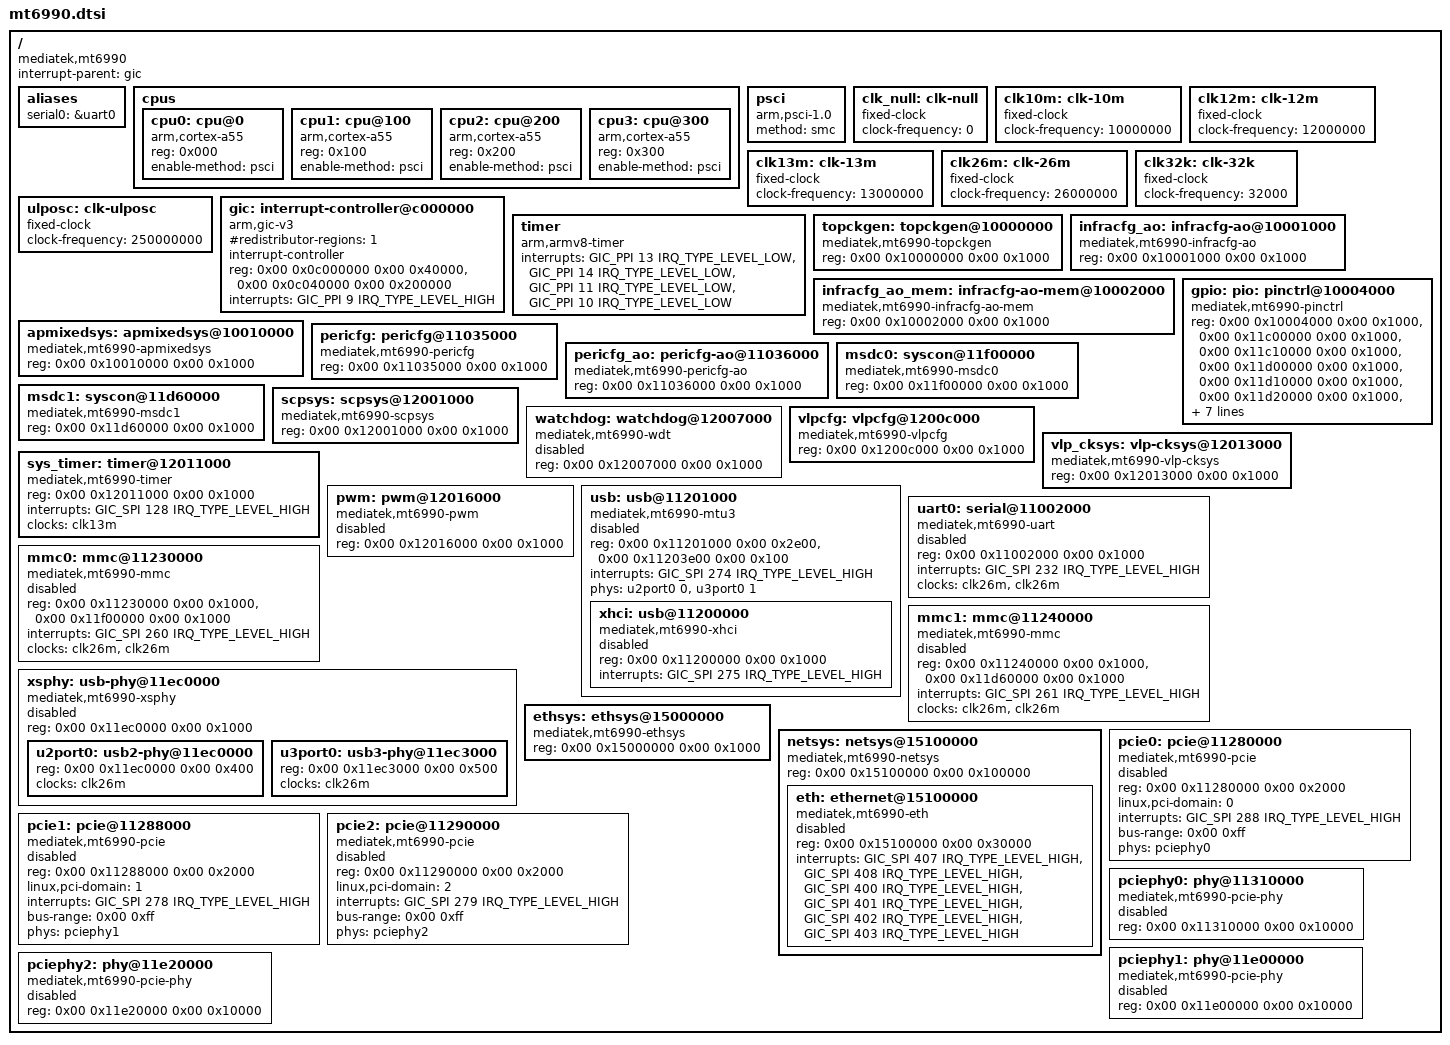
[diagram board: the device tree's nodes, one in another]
// SPDX-License-Identifier: GPL-2.0-only OR MIT
/*
 * MediaTek MT6990 / T830 SoC device tree.
 *
 * Source policy:
 *   - SoC facts are reconstructed from the running LG6851F live FDT
 *     (/sys/firmware/fdt) and the official boot_a DTB decompile.
 *   - Layout follows Linux/OpenWrt mainline-style MediaTek DTSI practice.
 *
 * This file describes MT6990 SoC blocks only. LG6851F board hardware remains
 * in mt6990-fiberhome-lg6851f.dts.
 */

#include <dt-bindings/interrupt-controller/arm-gic.h>
#include <dt-bindings/interrupt-controller/irq.h>
#include <dt-bindings/gpio/gpio.h>

/ {
	compatible = "mediatek,mt6990";
	interrupt-parent = <&gic>;
	#address-cells = <2>;
	#size-cells = <2>;

	aliases {
		serial0 = &uart0;
	};

	cpus {
		#address-cells = <1>;
		#size-cells = <0>;

		cpu0: cpu@0 {
			device_type = "cpu";
			compatible = "arm,cortex-a55";
			reg = <0x000>;
			enable-method = "psci";
		};

		cpu1: cpu@100 {
			device_type = "cpu";
			compatible = "arm,cortex-a55";
			reg = <0x100>;
			enable-method = "psci";
		};

		cpu2: cpu@200 {
			device_type = "cpu";
			compatible = "arm,cortex-a55";
			reg = <0x200>;
			enable-method = "psci";
		};

		cpu3: cpu@300 {
			device_type = "cpu";
			compatible = "arm,cortex-a55";
			reg = <0x300>;
			enable-method = "psci";
		};
	};

	psci {
		compatible = "arm,psci-1.0";
		method = "smc";
	};

	clk_null: clk-null {
		compatible = "fixed-clock";
		#clock-cells = <0>;
		clock-frequency = <0>;
	};

	clk10m: clk-10m {
		compatible = "fixed-clock";
		#clock-cells = <0>;
		clock-frequency = <10000000>;
	};

	clk12m: clk-12m {
		compatible = "fixed-clock";
		#clock-cells = <0>;
		clock-frequency = <12000000>;
	};

	clk13m: clk-13m {
		compatible = "fixed-clock";
		#clock-cells = <0>;
		clock-frequency = <13000000>;
	};

	clk26m: clk-26m {
		compatible = "fixed-clock";
		#clock-cells = <0>;
		clock-frequency = <26000000>;
	};

	clk32k: clk-32k {
		compatible = "fixed-clock";
		#clock-cells = <0>;
		clock-frequency = <32000>;
	};

	ulposc: clk-ulposc {
		compatible = "fixed-clock";
		#clock-cells = <0>;
		clock-frequency = <250000000>;
	};

	gic: interrupt-controller@c000000 {
		compatible = "arm,gic-v3";
		#interrupt-cells = <3>;
		#address-cells = <2>;
		#size-cells = <2>;
		#redistributor-regions = <1>;
		interrupt-controller;
		reg = <0x00 0x0c000000 0x00 0x40000>,
		      <0x00 0x0c040000 0x00 0x200000>;
		interrupts = <GIC_PPI 9 IRQ_TYPE_LEVEL_HIGH>;
	};

	timer {
		compatible = "arm,armv8-timer";
		interrupts = <GIC_PPI 13 IRQ_TYPE_LEVEL_LOW>,
			     <GIC_PPI 14 IRQ_TYPE_LEVEL_LOW>,
			     <GIC_PPI 11 IRQ_TYPE_LEVEL_LOW>,
			     <GIC_PPI 10 IRQ_TYPE_LEVEL_LOW>;
	};

	topckgen: topckgen@10000000 {
		compatible = "mediatek,mt6990-topckgen", "syscon";
		reg = <0x00 0x10000000 0x00 0x1000>;
		#clock-cells = <1>;
	};

	infracfg_ao: infracfg-ao@10001000 {
		compatible = "mediatek,mt6990-infracfg-ao", "syscon", "simple-mfd";
		reg = <0x00 0x10001000 0x00 0x1000>;
		#clock-cells = <1>;
	};

	infracfg_ao_mem: infracfg-ao-mem@10002000 {
		compatible = "mediatek,mt6990-infracfg-ao-mem", "syscon";
		reg = <0x00 0x10002000 0x00 0x1000>;
	};

	gpio: pio: pinctrl@10004000 {
		compatible = "mediatek,mt6990-pinctrl", "mediatek,mt69xx-pinctrl";
		reg = <0x00 0x10004000 0x00 0x1000>,
		      <0x00 0x11c00000 0x00 0x1000>,
		      <0x00 0x11c10000 0x00 0x1000>,
		      <0x00 0x11d00000 0x00 0x1000>,
		      <0x00 0x11d10000 0x00 0x1000>,
		      <0x00 0x11d20000 0x00 0x1000>,
		      <0x00 0x11d30000 0x00 0x1000>,
		      <0x00 0x11e80000 0x00 0x1000>,
		      <0x00 0x11e90000 0x00 0x1000>,
		      <0x00 0x11eb0000 0x00 0x1000>;
		reg-names = "gpio",
			    "iocfg_rt_8",
			    "iocfg_rt_9",
			    "iocfg_bm_4",
			    "iocfg_bm_5",
			    "iocfg_bm_6",
			    "iocfg_bm_7",
			    "iocfg_lt_0",
			    "iocfg_lt_1",
			    "iocfg_lt_3";
		gpio-controller;
		#gpio-cells = <2>;
		gpio-ranges = <&pio 0 0 226>;
		interrupt-controller;
		#interrupt-cells = <2>;
	};

	apmixedsys: apmixedsys@10010000 {
		compatible = "mediatek,mt6990-apmixedsys", "syscon";
		reg = <0x00 0x10010000 0x00 0x1000>;
		#clock-cells = <1>;
	};

	pericfg: pericfg@11035000 {
		compatible = "mediatek,mt6990-pericfg", "syscon";
		reg = <0x00 0x11035000 0x00 0x1000>;
	};

	pericfg_ao: pericfg-ao@11036000 {
		compatible = "mediatek,mt6990-pericfg-ao", "syscon";
		reg = <0x00 0x11036000 0x00 0x1000>;
		#clock-cells = <1>;
	};

	msdc0: syscon@11f00000 {
		compatible = "mediatek,mt6990-msdc0", "syscon";
		reg = <0x00 0x11f00000 0x00 0x1000>;
		#clock-cells = <1>;
	};

	msdc1: syscon@11d60000 {
		compatible = "mediatek,mt6990-msdc1", "syscon";
		reg = <0x00 0x11d60000 0x00 0x1000>;
		#clock-cells = <1>;
	};

	scpsys: scpsys@12001000 {
		compatible = "mediatek,mt6990-scpsys", "syscon";
		reg = <0x00 0x12001000 0x00 0x1000>;
		#power-domain-cells = <1>;
	};

	watchdog: watchdog@12007000 {
		compatible = "mediatek,mt6990-wdt", "mediatek,mt6880-wdt",
			     "mediatek,mt6589-wdt", "syscon";
		reg = <0x00 0x12007000 0x00 0x1000>;
		status = "disabled";
	};

	vlpcfg: vlpcfg@1200c000 {
		compatible = "mediatek,mt6990-vlpcfg", "syscon";
		reg = <0x00 0x1200c000 0x00 0x1000>;
		#clock-cells = <1>;
	};

	vlp_cksys: vlp-cksys@12013000 {
		compatible = "mediatek,mt6990-vlp-cksys", "mediatek,mt6990-vlp_cksys",
			     "syscon";
		reg = <0x00 0x12013000 0x00 0x1000>;
		#clock-cells = <1>;
	};

	sys_timer: timer@12011000 {
		compatible = "mediatek,mt6990-timer", "mediatek,mt6765-timer";
		reg = <0x00 0x12011000 0x00 0x1000>;
		interrupts = <GIC_SPI 128 IRQ_TYPE_LEVEL_HIGH>;
		clocks = <&clk13m>;
	};

	pwm: pwm@12016000 {
		compatible = "mediatek,mt6990-pwm";
		reg = <0x00 0x12016000 0x00 0x1000>;
		#pwm-cells = <2>;
		status = "disabled";
	};

	usb: usb@11201000 {
		compatible = "mediatek,mt6990-mtu3", "mediatek,mtu3";
		reg = <0x00 0x11201000 0x00 0x2e00>,
		      <0x00 0x11203e00 0x00 0x100>;
		reg-names = "mac", "ippc";
		interrupts = <GIC_SPI 274 IRQ_TYPE_LEVEL_HIGH>;
		phys = <&u2port0 0>, <&u3port0 1>;
		phy-names = "u2port0", "u3port0";
		#address-cells = <2>;
		#size-cells = <2>;
		ranges;
		status = "disabled";

		xhci: usb@11200000 {
			compatible = "mediatek,mt6990-xhci", "mediatek,mtk-xhci";
			reg = <0x00 0x11200000 0x00 0x1000>;
			interrupts = <GIC_SPI 275 IRQ_TYPE_LEVEL_HIGH>;
			status = "disabled";
		};
	};

	uart0: serial@11002000 {
		compatible = "mediatek,mt6990-uart", "mediatek,mt6577-uart";
		reg = <0x00 0x11002000 0x00 0x1000>;
		interrupts = <GIC_SPI 232 IRQ_TYPE_LEVEL_HIGH>;
		clocks = <&clk26m>, <&clk26m>;
		clock-names = "baud", "bus";
		status = "disabled";
	};

	mmc0: mmc@11230000 {
		compatible = "mediatek,mt6990-mmc", "mediatek,mt8183-mmc";
		reg = <0x00 0x11230000 0x00 0x1000>,
		      <0x00 0x11f00000 0x00 0x1000>;
		interrupts = <GIC_SPI 260 IRQ_TYPE_LEVEL_HIGH>;
		clocks = <&clk26m>, <&clk26m>;
		clock-names = "source", "hclk";
		status = "disabled";
	};

	mmc1: mmc@11240000 {
		compatible = "mediatek,mt6990-mmc", "mediatek,mt8183-mmc";
		reg = <0x00 0x11240000 0x00 0x1000>,
		      <0x00 0x11d60000 0x00 0x1000>;
		interrupts = <GIC_SPI 261 IRQ_TYPE_LEVEL_HIGH>;
		clocks = <&clk26m>, <&clk26m>;
		clock-names = "source", "hclk";
		status = "disabled";
	};

	xsphy: usb-phy@11ec0000 {
		compatible = "mediatek,mt6990-xsphy", "mediatek,xsphy";
		reg = <0x00 0x11ec0000 0x00 0x1000>;
		#address-cells = <2>;
		#size-cells = <2>;
		ranges;
		status = "disabled";

		u2port0: usb2-phy@11ec0000 {
			reg = <0x00 0x11ec0000 0x00 0x400>;
			clocks = <&clk26m>;
			clock-names = "ref";
			#phy-cells = <1>;
		};

		u3port0: usb3-phy@11ec3000 {
			reg = <0x00 0x11ec3000 0x00 0x500>;
			clocks = <&clk26m>;
			clock-names = "ref";
			#phy-cells = <1>;
		};
	};

	ethsys: ethsys@15000000 {
		compatible = "mediatek,mt6990-ethsys", "syscon";
		reg = <0x00 0x15000000 0x00 0x1000>;
	};

	netsys: netsys@15100000 {
		compatible = "mediatek,mt6990-netsys";
		reg = <0x00 0x15100000 0x00 0x100000>;
		#address-cells = <2>;
		#size-cells = <2>;
		ranges;

		eth: ethernet@15100000 {
			compatible = "mediatek,mt6990-eth";
			reg = <0x00 0x15100000 0x00 0x30000>;
			interrupts = <GIC_SPI 407 IRQ_TYPE_LEVEL_HIGH>,
				     <GIC_SPI 408 IRQ_TYPE_LEVEL_HIGH>,
				     <GIC_SPI 400 IRQ_TYPE_LEVEL_HIGH>,
				     <GIC_SPI 401 IRQ_TYPE_LEVEL_HIGH>,
				     <GIC_SPI 402 IRQ_TYPE_LEVEL_HIGH>,
				     <GIC_SPI 403 IRQ_TYPE_LEVEL_HIGH>;
			status = "disabled";
		};
	};

	pcie0: pcie@11280000 {
		compatible = "mediatek,mt6990-pcie";
		reg = <0x00 0x11280000 0x00 0x2000>;
		reg-names = "pcie-mac";
		linux,pci-domain = <0>;
		#address-cells = <3>;
		#size-cells = <2>;
		interrupts = <GIC_SPI 288 IRQ_TYPE_LEVEL_HIGH>;
		bus-range = <0x00 0xff>;
		ranges = <0x82000000 0x00 0x30000000 0x00 0x30000000 0x00 0x10000000>;
		phys = <&pciephy0>;
		phy-names = "pcie-phy";
		status = "disabled";
	};

	pcie1: pcie@11288000 {
		compatible = "mediatek,mt6990-pcie";
		reg = <0x00 0x11288000 0x00 0x2000>;
		reg-names = "pcie-mac";
		linux,pci-domain = <1>;
		#address-cells = <3>;
		#size-cells = <2>;
		interrupts = <GIC_SPI 278 IRQ_TYPE_LEVEL_HIGH>;
		bus-range = <0x00 0xff>;
		ranges = <0x82000000 0x00 0x40000000 0x00 0x40000000 0x00 0x04000000>;
		phys = <&pciephy1>;
		phy-names = "pcie-phy";
		status = "disabled";
	};

	pcie2: pcie@11290000 {
		compatible = "mediatek,mt6990-pcie";
		reg = <0x00 0x11290000 0x00 0x2000>;
		reg-names = "pcie-mac";
		linux,pci-domain = <2>;
		#address-cells = <3>;
		#size-cells = <2>;
		interrupts = <GIC_SPI 279 IRQ_TYPE_LEVEL_HIGH>;
		bus-range = <0x00 0xff>;
		ranges = <0x82000000 0x00 0x44000000 0x00 0x44000000 0x00 0x04000000>;
		phys = <&pciephy2>;
		phy-names = "pcie-phy";
		status = "disabled";
	};

	pciephy0: phy@11310000 {
		compatible = "mediatek,mt6990-pcie-phy";
		reg = <0x00 0x11310000 0x00 0x10000>;
		#phy-cells = <0>;
		status = "disabled";
	};

	pciephy1: phy@11e00000 {
		compatible = "mediatek,mt6990-pcie-phy";
		reg = <0x00 0x11e00000 0x00 0x10000>;
		#phy-cells = <0>;
		status = "disabled";
	};

	pciephy2: phy@11e20000 {
		compatible = "mediatek,mt6990-pcie-phy";
		reg = <0x00 0x11e20000 0x00 0x10000>;
		#phy-cells = <0>;
		status = "disabled";
	};
};
